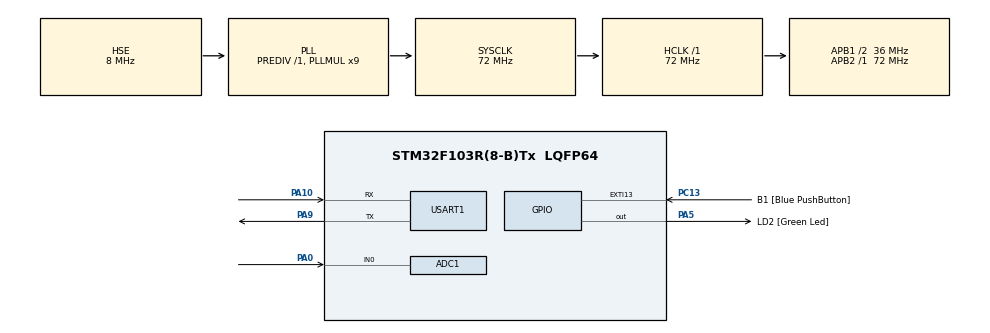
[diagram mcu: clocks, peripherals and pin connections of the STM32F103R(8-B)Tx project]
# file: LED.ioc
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ADC1.Channel-0\#ChannelRegularConversion=ADC_CHANNEL_0
ADC1.NbrOfConversionFlag=1
ADC1.Rank-0\#ChannelRegularConversion=1
ADC1.SamplingTime-0\#ChannelRegularConversion=ADC_SAMPLETIME_1CYCLE_5
ADC1.master=1
Mcu.Family=STM32F1
Mcu.Name=STM32F103R(8-B)Tx
Mcu.Package=LQFP64
NVIC.EXTI15_10_IRQn=true\:0\:0\:false\:false\:true\:true\:true\:true
NVIC.PriorityGroup=NVIC_PRIORITYGROUP_4
NVIC.TIM3_IRQn=true\:15\:0\:false\:false\:true\:false\:true\:true
NVIC.TimeBase=TIM3_IRQn
NVIC.TimeBaseIP=TIM3
PA0-WKUP.Signal=ADCx_IN0
PA10.Mode=Asynchronous
PA10.Signal=USART1_RX
PA5.GPIO_Label=LD2 [Green Led]
PA5.GPIO_ModeDefaultOutputPP=GPIO_MODE_OUTPUT_PP
PA5.GPIO_PuPd=GPIO_NOPULL
PA5.GPIO_Speed=GPIO_SPEED_FREQ_LOW
PA5.Signal=GPIO_Output
PA9.Mode=Asynchronous
PA9.Signal=USART1_TX
PC13-TAMPER-RTC.GPIO_Label=B1 [Blue PushButton]
PC13-TAMPER-RTC.GPIO_PuPd=GPIO_NOPULL
PC13-TAMPER-RTC.Signal=GPXTI13
PC14-OSC32_IN.Signal=RCC_OSC32_IN
PC15-OSC32_OUT.Signal=RCC_OSC32_OUT
PD0-OSC_IN.Mode=HSE-External-Oscillator
PD0-OSC_IN.Signal=RCC_OSC_IN
PD1-OSC_OUT.Mode=HSE-External-Oscillator
PD1-OSC_OUT.Signal=RCC_OSC_OUT
ProjectManager.HeapSize=0x200
ProjectManager.StackSize=0x400
ProjectManager.TargetToolchain=STM32CubeIDE
RCC.ADCPresc=RCC_ADCPCLK2_DIV6
RCC.AHBFreq_Value=72000000
RCC.APB1CLKDivider=RCC_HCLK_DIV2
RCC.APB1Freq_Value=36000000
RCC.APB1TimFreq_Value=72000000
RCC.APB2Freq_Value=72000000
RCC.APB2TimFreq_Value=72000000
RCC.HCLKFreq_Value=72000000
RCC.PLLMUL=RCC_PLL_MUL9
RCC.PLLSourceVirtual=RCC_PLLSOURCE_HSE
RCC.SYSCLKFreq_VALUE=72000000
RCC.SYSCLKSource=RCC_SYSCLKSOURCE_PLLCLK
RCC.USBFreq_Value=72000000
SH.ADCx_IN0.0=ADC1_IN0,IN0
USART1.VirtualMode=VM_ASYNC
VP_RTC_VS_RTC_Activate.Mode=RTC_Enabled
VP_RTC_VS_RTC_Calendar.Mode=RTC_Calendar
VP_SYS_VS_ND.Mode=No_Debug
VP_SYS_VS_tim3.Mode=TIM3
board=NUCLEO-F103RB

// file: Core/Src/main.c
/* USER CODE BEGIN Header */
/**
  ******************************************************************************
  * @file           : main.c
  * @brief          : Main program body
  ******************************************************************************
  * @attention
  *
  * Copyright (c) 2023 STMicroelectronics.
  * All rights reserved.
  *
  * This software is licensed under terms that can be found in the LICENSE file
  * in the root directory of this software component.
  * If no LICENSE file comes with this software, it is provided AS-IS.
  *
  ******************************************************************************
  */
/* USER CODE END Header */
#include "main.h"
#include <stdio.h>
#include <string.h>
#include <math.h>

ADC_HandleTypeDef hadc1;

RTC_HandleTypeDef hrtc;

UART_HandleTypeDef huart1;

char buffer[50];

uint32_t adc_value;

const float T0 = 25 + 273.15;
const float RT0 = 10000.0;
const float R0 = 10000.0;
const float B = 3950.0;

void SystemClock_Config(void);
static void MX_GPIO_Init(void);
static void MX_USART1_UART_Init(void);
static void MX_ADC1_Init(void);
static void MX_RTC_Init(void);

int main(void)
{

  /* MCU Configuration--------------------------------------------------------*/

  /* Reset of all peripherals, Initializes the Flash interface and the Systick. */
  HAL_Init();

  /* Configure the system clock */
  SystemClock_Config();

  /* Initialize all configured peripherals */
  MX_GPIO_Init();
  MX_USART1_UART_Init();
  MX_ADC1_Init();
  MX_RTC_Init();

  /* Infinite loop */
  /* USER CODE BEGIN WHILE */
  while (1)
  {
	  HAL_ADC_Start(&hadc1);
	  HAL_ADC_PollForConversion(&hadc1, 300);
	  adc_value = HAL_ADC_GetValue(&hadc1);
	  float T=1/((1/T0) + (1/B)*log((R0/RT0)*((4096.0/adc_value)-1))) - 273.15;
	  sprintf(buffer, "La temperature est : %.2f\r\n",T);
	  HAL_UART_Transmit(&huart1, (uint8_t*)buffer, strlen(buffer), 300);
	  HAL_Delay(5000);
	  GPIOA->ODR ^= (1 << 5);
    /* USER CODE END WHILE */

  }
}

void SystemClock_Config(void)
{
  RCC_OscInitTypeDef RCC_OscInitStruct = {0};
  RCC_ClkInitTypeDef RCC_ClkInitStruct = {0};
  RCC_PeriphCLKInitTypeDef PeriphClkInit = {0};

  /** Initializes the RCC Oscillators according to the specified parameters
  * in the RCC_OscInitTypeDef structure.
  */
  RCC_OscInitStruct.OscillatorType = RCC_OSCILLATORTYPE_LSI|RCC_OSCILLATORTYPE_HSE;
  RCC_OscInitStruct.HSEState = RCC_HSE_ON;
  RCC_OscInitStruct.HSEPredivValue = RCC_HSE_PREDIV_DIV1;
  RCC_OscInitStruct.HSIState = RCC_HSI_ON;
  RCC_OscInitStruct.LSIState = RCC_LSI_ON;
  RCC_OscInitStruct.PLL.PLLState = RCC_PLL_ON;
  RCC_OscInitStruct.PLL.PLLSource = RCC_PLLSOURCE_HSE;
  RCC_OscInitStruct.PLL.PLLMUL = RCC_PLL_MUL9;
  if (HAL_RCC_OscConfig(&RCC_OscInitStruct) != HAL_OK)
  {
    Error_Handler();
  }

  /** Initializes the CPU, AHB and APB buses clocks
  */
  RCC_ClkInitStruct.ClockType = RCC_CLOCKTYPE_HCLK|RCC_CLOCKTYPE_SYSCLK
                              |RCC_CLOCKTYPE_PCLK1|RCC_CLOCKTYPE_PCLK2;
  RCC_ClkInitStruct.SYSCLKSource = RCC_SYSCLKSOURCE_PLLCLK;
  RCC_ClkInitStruct.AHBCLKDivider = RCC_SYSCLK_DIV1;
  RCC_ClkInitStruct.APB1CLKDivider = RCC_HCLK_DIV2;
  RCC_ClkInitStruct.APB2CLKDivider = RCC_HCLK_DIV1;

  if (HAL_RCC_ClockConfig(&RCC_ClkInitStruct, FLASH_LATENCY_2) != HAL_OK)
  {
    Error_Handler();
  }
  PeriphClkInit.PeriphClockSelection = RCC_PERIPHCLK_RTC|RCC_PERIPHCLK_ADC;
  PeriphClkInit.RTCClockSelection = RCC_RTCCLKSOURCE_LSI;
  PeriphClkInit.AdcClockSelection = RCC_ADCPCLK2_DIV6;
  if (HAL_RCCEx_PeriphCLKConfig(&PeriphClkInit) != HAL_OK)
  {
    Error_Handler();
  }
}

static void MX_ADC1_Init(void)
{

  ADC_ChannelConfTypeDef sConfig = {0};

  /** Common config
  */
  hadc1.Instance = ADC1;
  hadc1.Init.ScanConvMode = ADC_SCAN_DISABLE;
  hadc1.Init.ContinuousConvMode = DISABLE;
  hadc1.Init.DiscontinuousConvMode = DISABLE;
  hadc1.Init.ExternalTrigConv = ADC_SOFTWARE_START;
  hadc1.Init.DataAlign = ADC_DATAALIGN_RIGHT;
  hadc1.Init.NbrOfConversion = 1;
  if (HAL_ADC_Init(&hadc1) != HAL_OK)
  {
    Error_Handler();
  }

  /** Configure Regular Channel
  */
  sConfig.Channel = ADC_CHANNEL_0;
  sConfig.Rank = ADC_REGULAR_RANK_1;
  sConfig.SamplingTime = ADC_SAMPLETIME_1CYCLE_5;
  if (HAL_ADC_ConfigChannel(&hadc1, &sConfig) != HAL_OK)
  {
    Error_Handler();
  }

}

static void MX_RTC_Init(void)
{

  RTC_TimeTypeDef sTime = {0};
  RTC_DateTypeDef DateToUpdate = {0};

  /** Initialize RTC Only
  */
  hrtc.Instance = RTC;
  hrtc.Init.AsynchPrediv = RTC_AUTO_1_SECOND;
  hrtc.Init.OutPut = RTC_OUTPUTSOURCE_ALARM;
  if (HAL_RTC_Init(&hrtc) != HAL_OK)
  {
    Error_Handler();
  }

  /** Initialize RTC and set the Time and Date
  */
  sTime.Hours = 0x0;
  sTime.Minutes = 0x0;
  sTime.Seconds = 0x0;

  if (HAL_RTC_SetTime(&hrtc, &sTime, RTC_FORMAT_BCD) != HAL_OK)
  {
    Error_Handler();
  }
  DateToUpdate.WeekDay = RTC_WEEKDAY_MONDAY;
  DateToUpdate.Month = RTC_MONTH_JANUARY;
  DateToUpdate.Date = 0x1;
  DateToUpdate.Year = 0x0;

  if (HAL_RTC_SetDate(&hrtc, &DateToUpdate, RTC_FORMAT_BCD) != HAL_OK)
  {
    Error_Handler();
  }

}

static void MX_USART1_UART_Init(void)
{

  huart1.Instance = USART1;
  huart1.Init.BaudRate = 115200;
  huart1.Init.WordLength = UART_WORDLENGTH_8B;
  huart1.Init.StopBits = UART_STOPBITS_1;
  huart1.Init.Parity = UART_PARITY_NONE;
  huart1.Init.Mode = UART_MODE_TX_RX;
  huart1.Init.HwFlowCtl = UART_HWCONTROL_NONE;
  huart1.Init.OverSampling = UART_OVERSAMPLING_16;
  if (HAL_UART_Init(&huart1) != HAL_OK)
  {
    Error_Handler();
  }

}

static void MX_GPIO_Init(void)
{
  GPIO_InitTypeDef GPIO_InitStruct = {0};

  /* GPIO Ports Clock Enable */
  __HAL_RCC_GPIOC_CLK_ENABLE();
  __HAL_RCC_GPIOD_CLK_ENABLE();
  __HAL_RCC_GPIOA_CLK_ENABLE();

  /*Configure GPIO pin Output Level */
  HAL_GPIO_WritePin(LD2_GPIO_Port, LD2_Pin, GPIO_PIN_RESET);

  /*Configure GPIO pin : B1_Pin */
  GPIO_InitStruct.Pin = B1_Pin;
  GPIO_InitStruct.Mode = GPIO_MODE_IT_RISING;
  GPIO_InitStruct.Pull = GPIO_NOPULL;
  HAL_GPIO_Init(B1_GPIO_Port, &GPIO_InitStruct);

  /*Configure GPIO pin : LD2_Pin */
  GPIO_InitStruct.Pin = LD2_Pin;
  GPIO_InitStruct.Mode = GPIO_MODE_OUTPUT_PP;
  GPIO_InitStruct.Pull = GPIO_NOPULL;
  GPIO_InitStruct.Speed = GPIO_SPEED_FREQ_LOW;
  HAL_GPIO_Init(LD2_GPIO_Port, &GPIO_InitStruct);

  /* EXTI interrupt init*/
  HAL_NVIC_SetPriority(EXTI15_10_IRQn, 0, 0);
  HAL_NVIC_EnableIRQ(EXTI15_10_IRQn);

}

void HAL_TIM_PeriodElapsedCallback(TIM_HandleTypeDef *htim)
{
  if (htim->Instance == TIM3) {
    HAL_IncTick();
  }
}

void Error_Handler(void)
{
  __disable_irq();
  while (1)
  {
  }
}
